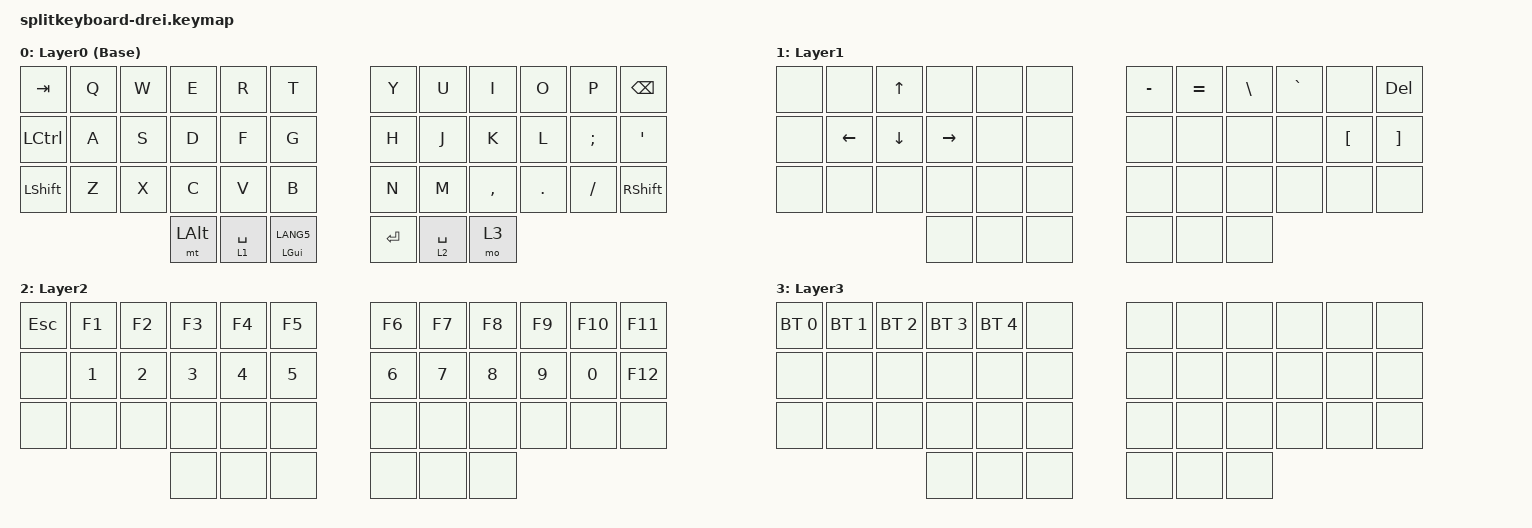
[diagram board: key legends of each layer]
#include <behaviors.dtsi>
#include <dt-bindings/zmk/keys.h>

/ {
    keymap {
        compatible = "zmk,keymap";

        default_layer {
            display-name = "Layer0 (Base)";

            // ---------------------------------------------------------------------------------------------------------------------
            // | TAB    | Q | W | E     | R              | T              |  | Y     | U              | I        | O | P | BSPC   |
            // | CTRL   | A | S | D     | F              | G              |  | H     | J              | K        | L | ; | '      |
            // | LSHIFT | Z | X | C     | V              | B              |  | N     | M              | ,        | . | / | RSHIFT |
            //                  | (ALT) | SPACE (Layer1) | 半角/全角 (Win) |  | Enter | SPACE (Layer2) | (Layer3) |
            bindings = <
                &kp TAB    &kp Q  &kp W  &kp E    &kp R        &kp T             &kp Y      &kp U        &kp I      &kp O       &kp P     &kp BSPC
                &kp LCTRL  &kp A  &kp S  &kp D    &kp F        &kp G             &kp H      &kp J        &kp K      &kp L       &kp SEMI  &kp SQT
                &kp LSHIFT &kp Z  &kp X  &kp C    &kp V        &kp B             &kp N      &kp M        &kp COMMA  &kp PERIOD  &kp FSLH  &kp RSHIFT
                                         &mt LALT &lt 1 SPACE  &mt LGUI LANG5    &kp ENTER  &lt 2 SPACE  &mo 3
            >;
        };

        Layer1 {
            display-name = "Layer1";
            
            // --------------------------------------------------------
            // |   |   | ↑ |   |   |   |  | - | = | \ | ` |   | Del |
            // |   | ← | ↓ | → |   |   |  |   |   |   |   | [ | ]   |
            // |   |   |   |   |   |   |  |   |   |   |   |   |     |
            //             |   |   |   |  |   |   |   |
            bindings = <
                &none  &none     &kp UP    &none      &none  &none    &kp MINUS  &kp EQUAL  &kp BSLH  &kp GRAVE  &none    &kp DEL
                &none  &kp LEFT  &kp DOWN  &kp RIGHT  &none  &none    &none      &none      &none     &none      &kp LBKT &kp RBKT
                &none  &none     &none     &none      &none  &none    &none      &none      &none     &none      &none    &none
                                           &none      &none  &none    &none      &none      &none
            >;
        };

        Layer2 {
            display-name = "Layer2";
            
            // --------------------------------------------------------------------
            // | ESC | F1 | F2 | F3 | F4 | F5 |  | F6 | F7 | F8 | F9 | F10 | F11 |
            // |     | 1  | 2  | 3  | 4  | 5  |  | 6  | 7  | 8  | 9  | 0   | F12 |
            // |     |    |    |    |    |    |  |    |    |    |    |     |     |
            //                 |    |    |    |  |    |    |    |
            bindings = <
                &kp ESC  &kp F1  &kp F2  &kp F3  &kp F4  &kp F5    &kp F6  &kp F7  &kp F8  &kp F9  &kp F10  &kp F11
                &none    &kp N1  &kp N2  &kp N3  &kp N4  &kp N5    &kp N6  &kp N7  &kp N8  &kp N9  &kp N0   &kp F12
                &none    &none   &none   &none   &none   &none     &none   &none   &none   &none   &none    &none
                                         &none   &none   &none     &none   &none   &none
            >;
        };

        Layer3 {
            display-name = "Layer3";
            
            bindings = <
                &bt BT_SEL 0  &bt BT_SEL 1  &bt BT_SEL 2  &bt BT_SEL 3  &bt BT_SEL 4  &none    &none  &none  &none  &none  &none  &none
                &none         &none         &none         &none         &none         &none    &none  &none  &none  &none  &none  &none
                &none         &none         &none         &none         &none         &none    &none  &none  &none  &none  &none  &none
                                                          &none         &none         &none    &none  &none  &none
            >;
        };
    };
 };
